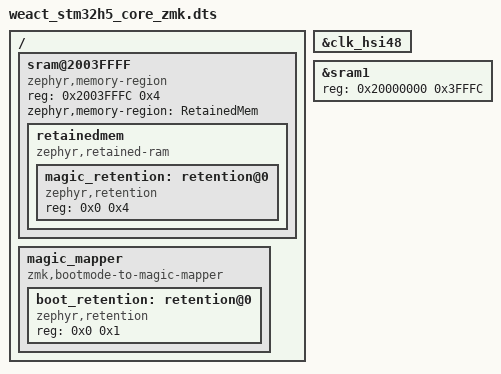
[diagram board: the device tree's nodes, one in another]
#include <../boards/weact/stm32h5_core/weact_stm32h5_core.dts>

&clk_hsi48 {
    status = "okay";
};

&sram1 {
    reg = <0x20000000 0x3FFFC>;
};

/ {
    sram@2003FFFF {
        compatible = "zephyr,memory-region", "mmio-sram";
        reg = <0x2003FFFC 0x4>;
        zephyr,memory-region = "RetainedMem";
        status = "okay";

        retainedmem {
            compatible = "zephyr,retained-ram";
            status = "okay";
            #address-cells = <1>;
            #size-cells = <1>;

            magic_retention: retention@0 {
                compatible = "zephyr,retention";
                status = "okay";
                reg = <0x0 0x4>;
            };
        };
    };
};

/ {
    magic_mapper {
        compatible = "zmk,bootmode-to-magic-mapper";
        status = "okay";

        #address-cells = <1>;
        #size-cells = <1>;

        boot_retention: retention@0 {
            compatible = "zephyr,retention";
            status = "okay";
            reg = <0x0 0x1>;
        };
    };
};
